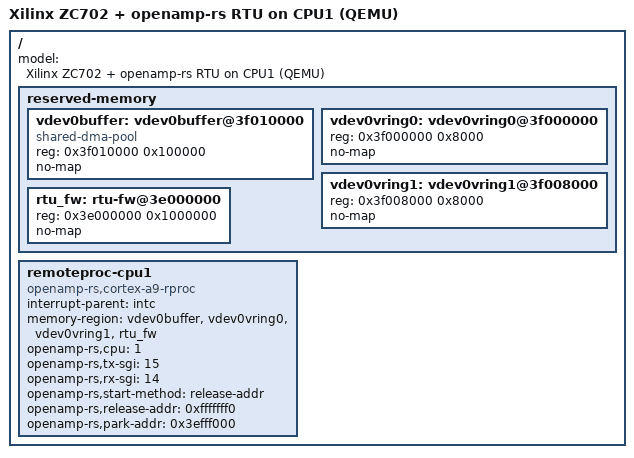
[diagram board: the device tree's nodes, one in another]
// SPDX-License-Identifier: GPL-2.0
/*
 * ZC702 with CPU1 handed to the openamp-rs RTU, for QEMU's xilinx-zynq-a9.
 *
 * Linux runs on CPU0 only (maxcpus=1 on the command line). The top 32 MiB
 * of the first GiB is the RTU's (see examples/cortex-a9-rtu-echo/src/board.rs).
 * CPU1 waits in the boot ROM's loop for an entry address at 0xfffffff0
 * (on real hardware after the FSBL; under QEMU in run.sh's boot-cpu1.S).
 */
/dts-v1/;
#include "zynq-zc702.dts"

/ {
	model = "Xilinx ZC702 + openamp-rs RTU on CPU1 (QEMU)";

	reserved-memory {
		#address-cells = <1>;
		#size-cells = <1>;
		ranges;

		/* rpmsg buffers: index 0, assigned to the vdev by remoteproc */
		vdev0buffer: vdev0buffer@3f010000 {
			compatible = "shared-dma-pool";
			reg = <0x3f010000 0x100000>;
			no-map;
		};

		vdev0vring0: vdev0vring0@3f000000 {
			reg = <0x3f000000 0x8000>;
			no-map;
		};

		vdev0vring1: vdev0vring1@3f008000 {
			reg = <0x3f008000 0x8000>;
			no-map;
		};

		/* firmware image, resource table and park page */
		rtu_fw: rtu-fw@3e000000 {
			reg = <0x3e000000 0x1000000>;
			no-map;
		};
	};

	remoteproc-cpu1 {
		compatible = "openamp-rs,cortex-a9-rproc";
		interrupt-parent = <&intc>;
		memory-region = <&vdev0buffer>, <&vdev0vring0>, <&vdev0vring1>, <&rtu_fw>;
		openamp-rs,cpu = <1>;
		openamp-rs,tx-sgi = <15>;
		openamp-rs,rx-sgi = <14>;
		openamp-rs,start-method = "release-addr";
		openamp-rs,release-addr = <0xfffffff0>;
		openamp-rs,park-addr = <0x3efff000>;
	};
};
